AUTOSAR XML (schema 4-3-0)
package /MICROSAR/Dcm_swc
  4 x mode declaration group, all with category=EXPLICIT_ORDER:
    DcmControlDtcSetting: initial-mode=ENABLEDTCSETTING, on-transition-value=2
      mode ENABLEDTCSETTING: value=0
      mode DISABLEDTCSETTING: value=1
    DcmEcuReset: initial-mode=NONE, on-transition-value=7
      7 x mode:
        NONE: value=0
        HARD: value=1
        KEYONOFF: value=2
        SOFT: value=3
        JUMPTOBOOTLOADER: value=4
        JUMPTOSYSSUPPLIERBOOTLOADER: value=5
        EXECUTE: value=6
    DcmDiagnosticSessionControl: initial-mode=DefaultSession, on-transition-value=255
      mode DefaultSession: value=1
      mode ProgrammingSession: value=2
      mode ExtendedSession: value=3
    DcmCommunicationControl: initial-mode=DCM_ENABLE_RX_TX_NORM, on-transition-value=12
      12 x mode:
        DCM_ENABLE_RX_TX_NORM: value=0
        DCM_ENABLE_RX_DISABLE_TX_NORM: value=1
        DCM_DISABLE_RX_ENABLE_TX_NORM: value=2
        DCM_DISABLE_RX_TX_NORMAL: value=3
        DCM_ENABLE_RX_TX_NM: value=4
        DCM_ENABLE_RX_DISABLE_TX_NM: value=5
        DCM_DISABLE_RX_ENABLE_TX_NM: value=6
        DCM_DISABLE_RX_TX_NM: value=7
        DCM_ENABLE_RX_TX_NORM_NM: value=8
        DCM_ENABLE_RX_DISABLE_TX_NORM_NM: value=9
        DCM_DISABLE_RX_ENABLE_TX_NORM_NM: value=10
        DCM_DISABLE_RX_TX_NORM_NM: value=11
  data type mapping set DcmMappingSet  # Contains mapping for ModeDeclarationGroups which are provided by Dcm.
    mode-request-type-maps:
      implementation-data-type=Dcm_ControlDtcSettingType, mode-group=DcmControlDtcSetting
      implementation-data-type=Dcm_EcuResetType, mode-group=DcmEcuReset
      implementation-data-type=Dcm_DiagnosticSessionControlType, mode-group=DcmDiagnosticSessionControl
      implementation-data-type=Dcm_CommunicationModeType, mode-group=DcmCommunicationControl
package /MICROSAR/Dcm_swc/DataTypes
  17 x impl type:
    Dcm_ConfirmationStatusType: compu {0=DCM_RES_POS_OK, 1=DCM_RES_POS_NOT_OK, 2=DCM_RES_NEG_OK, 3=DCM_RES_NEG_NOT_OK}, implementation-data-type=uint8
    Dcm_OpStatusType: compu {0=DCM_INITIAL, 1=DCM_PENDING, 2=DCM_CANCEL, 3=DCM_FORCE_RCRRP_OK, 64=DCM_FORCE_RCRRP_NOT_OK}, implementation-data-type=uint8
    Dcm_NegativeResponseCodeType: compu {0=DCM_E_POSITIVERESPONSE, 16=DCM_E_GENERALREJECT, 17=DCM_E_SERVICENOTSUPPORTED, 18=DCM_E_SUBFUNCTIONNOTSUPPORTED, 19=DCM_E_INCORRECTMESSAGELENGTHORINVALIDFORMAT, 20=DCM_E_RESPONSETOOLONG, 33=DCM_E_BUSYREPEATREQUEST, 34=DCM_E_CONDITIONSNOTCORRECT, 36=DCM_E_REQUESTSEQUENCEERROR, 37=DCM_E_NORESPONSEFROMSUBNETCOMPONENT, 38=DCM_E_FAILUREPREVENTSEXECUTIONOFREQUESTEDACTION, 49=DCM_E_REQUESTOUTOFRANGE, 51=DCM_E_SECURITYACCESSDENIED, 53=DCM_E_INVALIDKEY, 54=DCM_E_EXCEEDNUMBEROFATTEMPTS, 55=DCM_E_REQUIREDTIMEDELAYNOTEXPIRED, 112=DCM_E_UPLOADDOWNLOADNOTACCEPTED, 113=DCM_E_TRANSFERDATASUSPENDED, 114=DCM_E_GENERALPROGRAMMINGFAILURE, 115=DCM_E_WRONGBLOCKSEQUENCECOUNTER, 120=DCM_E_REQUESTCORRECTLYRECEIVEDRESPONSEPENDING, 126=DCM_E_SUBFUNCTIONNOTSUPPORTEDINACTIVESESSION, 127=DCM_E_SERVICENOTSUPPORTEDINACTIVESESSION, 129=DCM_E_RPMTOOHIGH, 130=DCM_E_RPMTOOLOW, 131=DCM_E_ENGINEISRUNNING, 132=DCM_E_ENGINEISNOTRUNNING, 133=DCM_E_ENGINERUNTIMETOOLOW, 134=DCM_E_TEMPERATURETOOHIGH, 135=DCM_E_TEMPERATURETOOLOW, 136=DCM_E_VEHICLESPEEDTOOHIGH, 137=DCM_E_VEHICLESPEEDTOOLOW, 138=DCM_E_THROTTLE_PEDALTOOHIGH, 139=DCM_E_THROTTLE_PEDALTOOLOW, 140=DCM_E_TRANSMISSIONRANGENOTINNEUTRAL, 141=DCM_E_TRANSMISSIONRANGENOTINGEAR, 143=DCM_E_BRAKESWITCH_NOTCLOSED, 144=DCM_E_SHIFTERLEVERNOTINPARK, 145=DCM_E_TORQUECONVERTERCLUTCHLOCKED, 146=DCM_E_VOLTAGETOOHIGH, 147=DCM_E_VOLTAGETOOLOW, 240..249=DCM_E_VMSCNC_0..DCM_E_VMSCNC_9, 250=DCM_E_VMSCNC_A, 251=DCM_E_VMSCNC_B, 252=DCM_E_VMSCNC_C, 253=DCM_E_VMSCNC_D, 254=DCM_E_VMSCNC_E}, implementation-data-type=uint8
    Dcm_ProtocolType: compu {0=DCM_OBD_ON_CAN, 1=DCM_OBD_ON_FLEXRAY, 2=DCM_OBD_ON_IP, 3=DCM_UDS_ON_CAN, 4=DCM_UDS_ON_FLEXRAY, 5=DCM_UDS_ON_IP, 12=DCM_NO_ACTIVE_PROTOCOL, 240..254=DCM_SUPPLIER_1..DCM_SUPPLIER_15}, implementation-data-type=uint8
    Dcm_RequestKindType: compu {0=DCM_REQ_KIND_NONE, 1=DCM_REQ_KIND_EXTERNAL, 2=DCM_REQ_KIND_ROE}, implementation-data-type=uint8
    Dcm_SecLevelType: compu {0=DCM_SEC_LEV_LOCKED, 9=DCM_SEC_LEV_L9}, implementation-data-type=uint8
    Dcm_SesCtrlType: compu {1=DCM_DEFAULT_SESSION, 2=DCM_PROGRAMMING_SESSION, 3=DCM_EXTENDED_DIAGNOSTIC_SESSION}, implementation-data-type=uint8
    Dem_DTCKindType: compu {1=DEM_DTC_KIND_ALL_DTCS, 2=DEM_DTC_KIND_EMISSION_REL_DTCS}, implementation-data-type=uint8
    Dem_DTCGroupType: range raw 0..16777215, implementation-data-type=uint32
    Dcm_ControlDtcSettingType: compu {0=DCM_ENUM_ENABLEDTCSETTING, 1=DCM_ENUM_DISABLEDTCSETTING}, implementation-data-type=uint8
    Dcm_EcuResetType: compu {0=DCM_ENUM_NONE, 1=DCM_ENUM_HARD, 2=DCM_ENUM_KEYONOFF, 3=DCM_ENUM_SOFT, 4=DCM_ENUM_JUMPTOBOOTLOADER, 5=DCM_ENUM_JUMPTOSYSSUPPLIERBOOTLOADER, 6=DCM_ENUM_EXECUTE}, implementation-data-type=uint8
    Dcm_DiagnosticSessionControlType: compu {1=DCM_ENUM_DefaultSession, 2=DCM_ENUM_ProgrammingSession, 3=DCM_ENUM_ExtendedSession}, implementation-data-type=uint8
    Dcm_CommunicationModeType: compu {0=DCM_ENABLE_RX_TX_NORM, 1=DCM_ENABLE_RX_DISABLE_TX_NORM, 2=DCM_DISABLE_RX_ENABLE_TX_NORM, 3=DCM_DISABLE_RX_TX_NORMAL, 4=DCM_ENABLE_RX_TX_NM, 5=DCM_ENABLE_RX_DISABLE_TX_NM, 6=DCM_DISABLE_RX_ENABLE_TX_NM, 7=DCM_DISABLE_RX_TX_NM, 8=DCM_ENABLE_RX_TX_NORM_NM, 9=DCM_ENABLE_RX_DISABLE_TX_NORM_NM, 10=DCM_DISABLE_RX_ENABLE_TX_NORM_NM, 11=DCM_DISABLE_RX_TX_NORM_NM}, implementation-data-type=uint8
    Dcm_Data4096ByteType: category=ARRAY, sw-calibration-access=READ-ONLY
      element Dcm_Data4096ByteTypeElement: array-size=4096, array-size-semantics=FIXED-SIZE, implementation-data-type=uint8
    Dcm_Data4ByteType: category=ARRAY, sw-calibration-access=READ-ONLY
      element Dcm_Data4ByteTypeElement: array-size=4, array-size-semantics=FIXED-SIZE, implementation-data-type=uint8
    Dcm_Data8ByteType: category=ARRAY, sw-calibration-access=READ-ONLY
      element Dcm_Data8ByteTypeElement: array-size=8, array-size-semantics=FIXED-SIZE, implementation-data-type=uint8
    Dcm_Data132ByteType: category=ARRAY, sw-calibration-access=READ-ONLY
      element Dcm_Data132ByteTypeElement: array-size=132, array-size-semantics=FIXED-SIZE, implementation-data-type=uint8
package /MICROSAR/Dcm_swc/Interfaces
  4 x mode switch interface, all with is-service=true, service-kind=DIAGNOSTIC-COMMUNICATION-MANAGER:
    DcmControlDtcSetting
      mode group DcmControlDtcSetting: type=DcmControlDtcSetting
    DcmEcuReset
      mode group DcmEcuReset: type=DcmEcuReset
    DcmDiagnosticSessionControl
      mode group DcmDiagnosticSessionControl: type=DcmDiagnosticSessionControl
    DcmCommunicationControl_ComMConf_ComMChannel_A_FlexRay_5b5a9ac2
      mode group DcmCommunicationControl_ComMConf_ComMChannel_A_FlexRay_5b5a9ac2: type=DcmCommunicationControl
  4 x client server interface, all with is-service=true, service-kind=DIAGNOSTIC-COMMUNICATION-MANAGER:
    DCMServices
      6 x operation:
        GetActiveProtocol: possible-error=E_OK
          arg ActiveProtocol: type=Dcm_ProtocolType, direction=OUT
        GetSesCtrlType: possible-error=E_OK
          arg SesCtrlType: type=Dcm_SesCtrlType, direction=OUT
        ResetToDefaultSession: possible-error=E_OK
        GetSecurityLevel: possible-error=E_OK
          arg SecLevel: type=Dcm_SecLevelType, direction=OUT
        SetActiveDiagnostic: possible-error=E_OK
          arg active: type=boolean, direction=IN
        GetRequestKind: possible-error=DCMServices/E_NOT_OK
          arg TesterSourceAddress: type=uint16, direction=IN
          arg RequestKind: type=Dcm_RequestKindType, direction=OUT
      error E_OK: error-code=0
      error E_NOT_OK: error-code=1
    ServiceRequestNotification
      operation Indication: possible-error=[ServiceRequestNotification/E_NOT_OK, E_REQUEST_NOT_ACCEPTED]
        6 x arg:
          SID: type=uint8, direction=IN
          RequestData: type=Dcm_Data4096ByteType, direction=IN
          DataSize: type=uint16, direction=IN
          ReqType: type=uint8, direction=IN
          SourceAddress: type=uint16, direction=IN
          ErrorCode: type=Dcm_NegativeResponseCodeType, direction=OUT
      operation Confirmation: possible-error=ServiceRequestNotification/E_NOT_OK
        4 x arg, all with direction=IN:
          SID: type=uint8
          ReqType: type=uint8
          SourceAddress: type=uint16
          ConfirmationStatus: type=Dcm_ConfirmationStatusType
      error E_NOT_OK: error-code=1
      error E_REQUEST_NOT_ACCEPTED: error-code=8
    SecurityAccess_UNLOCKED_LVL_09
      operation GetSeed: possible-error=[SecurityAccess_UNLOCKED_LVL_09/E_NOT_OK, DCM_E_PENDING]
        4 x arg:
          SecurityAccessDataRecord: type=Dcm_Data4ByteType, direction=IN
          OpStatus: type=Dcm_OpStatusType, direction=IN
          Seed: type=Dcm_Data8ByteType, direction=OUT
          ErrorCode: type=Dcm_NegativeResponseCodeType, direction=OUT
      operation CompareKey: possible-error=[SecurityAccess_UNLOCKED_LVL_09/E_NOT_OK, DCM_E_PENDING, DCM_E_COMPARE_KEY_FAILED]
        arg Key: type=Dcm_Data132ByteType, direction=IN
        arg OpStatus: type=Dcm_OpStatusType, direction=IN
        arg ErrorCode: type=Dcm_NegativeResponseCodeType, direction=OUT
      error E_NOT_OK: error-code=1
      error DCM_E_PENDING: error-code=10
      error DCM_E_COMPARE_KEY_FAILED: error-code=11
    DcmIf
      operation DcmEnableDTCSetting: possible-error=[DEM_CONTROL_DTC_SETTING_N_OK, DEM_CONTROL_DTC_WRONG_DTCGROUP]
        arg DTCGroup: type=Dem_DTCGroupType, direction=IN
        arg DTCKind: type=Dem_DTCKindType, direction=IN
      error DEM_CONTROL_DTC_SETTING_N_OK: error-code=1
      error DEM_CONTROL_DTC_WRONG_DTCGROUP: error-code=2
package /MICROSAR/Dcm_swc/ComponentTypes
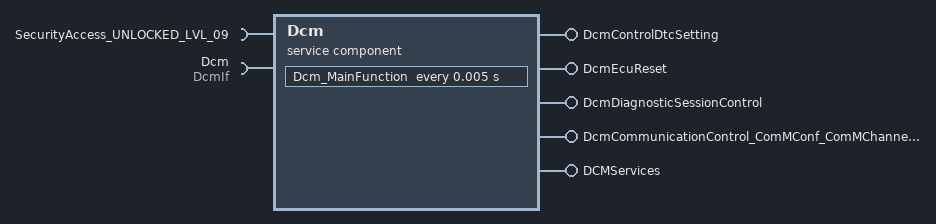
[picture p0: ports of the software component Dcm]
  service sw component type Dcm: category=SERVICE_COMPONENT
    5 x provide port:
      DcmControlDtcSetting: provided-interface=DcmControlDtcSetting
      DcmEcuReset: mode-switch-sender-com-spec{mode-group=DcmEcuReset, mode-switched-ack=timeout=0}, provided-interface=DcmEcuReset
      DcmDiagnosticSessionControl: provided-interface=DcmDiagnosticSessionControl
      DcmCommunicationControl_ComMConf_ComMChannel_A_FlexRay_5b5a9ac2: provided-interface=DcmCommunicationControl_ComMConf_ComMChannel_A_FlexRay_5b5a9ac2
      DCMServices: provided-interface=DCMServices
    require port SecurityAccess_UNLOCKED_LVL_09: required-interface=SecurityAccess_UNLOCKED_LVL_09
    require port Dcm: required-interface=DcmIf
    behavior DcmInternalBehavior: data-type-mapping=DcmMappingSet, handle-termination-and-restart=NO-SUPPORT, included-data-type-set=data-type=[Dcm_ConfirmationStatusType, Dcm_OpStatusType, Dcm_NegativeResponseCodeType, Dcm_ProtocolType, Dcm_RequestKindType, Dcm_SecLevelType, Dcm_SesCtrlType, Dcm_ControlDtcSettingType, Dcm_EcuResetType, Dcm_DiagnosticSessionControlType, Dcm_CommunicationModeType]
      timing event Timer_Dcm_MainFunction: start-on-event=Dcm_MainFunction, period=0.005
      6 x operation invoked event:
        OpEventGetActiveProtocol_GetActiveProtocol_DCMServices: start-on-event=GetActiveProtocol, operation=DCMServices.GetActiveProtocol
        OpEventGetSesCtrlType_GetSesCtrlType_DCMServices: start-on-event=GetSesCtrlType, operation=DCMServices.GetSesCtrlType
        OpEventResetToDefaultSession_ResetToDefaultSession_DCMServices: start-on-event=ResetToDefaultSession, operation=DCMServices.ResetToDefaultSession
        OpEventGetSecurityLevel_GetSecurityLevel_DCMServices: start-on-event=GetSecurityLevel, operation=DCMServices.GetSecurityLevel
        OpEventSetActiveDiagnostic_SetActiveDiagnostic_DCMServices: start-on-event=SetActiveDiagnostic, operation=DCMServices.SetActiveDiagnostic
        OpEventGetRequestKind_GetRequestKind_DCMServices: start-on-event=GetRequestKind, operation=DCMServices.GetRequestKind
      port-api-options:
        enable-take-address=true, indirect-api=false, port=DcmControlDtcSetting
        enable-take-address=true, indirect-api=false, port=DcmEcuReset
        enable-take-address=true, indirect-api=false, port=DcmDiagnosticSessionControl
        enable-take-address=true, indirect-api=false, port=DcmCommunicationControl_ComMConf_ComMChannel_A_FlexRay_5b5a9ac2
        enable-take-address=true, indirect-api=false, port=DCMServices
        enable-take-address=true, indirect-api=false, port=SecurityAccess_UNLOCKED_LVL_09
        enable-take-address=true, indirect-api=false, port=Dcm
      7 x runnable:
        Dcm_MainFunction
          4 x mode switch point:
            ModeSwitchPointDcm_MainFunction_DcmControlDtcSetting_DcmControlDtcSetting: mode-group=DcmControlDtcSetting.DcmControlDtcSetting
            ModeSwitchPointDcm_MainFunction_DcmEcuReset_DcmEcuReset: mode-group=DcmEcuReset.DcmEcuReset
            ModeSwitchPointDcm_MainFunction_DcmDiagnosticSessionControl_DcmDiagnosticSessionControl: mode-group=DcmDiagnosticSessionControl.DcmDiagnosticSessionControl
            ModeSwitchPointDcm_MainFunction_DcmCommunicationControl_ComMConf_ComMChannel_A_FlexRay_5b5a9ac2_DcmCommunicationControl_aef52ce2: mode-group=DcmCommunicationControl_ComMConf_ComMChannel_A_FlexRay_5b5a9ac2.DcmCommunicationControl_ComMConf_ComMChannel_A_FlexRay_5b5a9ac2
          sync call OpServerCallDcm_MainFunction_GetSeed_SecurityAccess_UNLOCKED_LVL_09: operation=SecurityAccess_UNLOCKED_LVL_09.GetSeed, timeout=0
          sync call OpServerCallDcm_MainFunction_CompareKey_SecurityAccess_UNLOCKED_LVL_09: operation=SecurityAccess_UNLOCKED_LVL_09.CompareKey, timeout=0
          sync call OpServerCallDcm_MainFunction_DcmEnableDTCSetting_Dcm: operation=Dcm.DcmEnableDTCSetting, timeout=0
        GetActiveProtocol: can-be-invoked-concurrently=true, symbol=Dcm_GetActiveProtocol
        GetSesCtrlType: can-be-invoked-concurrently=true, symbol=Dcm_GetSesCtrlType
        ResetToDefaultSession: can-be-invoked-concurrently=true, symbol=Dcm_ResetToDefaultSession
        GetSecurityLevel: can-be-invoked-concurrently=true, symbol=Dcm_GetSecurityLevel
        SetActiveDiagnostic: can-be-invoked-concurrently=true, symbol=Dcm_SetActiveDiagnostic
        GetRequestKind: can-be-invoked-concurrently=true, symbol=Dcm_GetRequestKind
  swc implementation DcmImplementation: programming-language=C, behavior=DcmInternalBehavior
